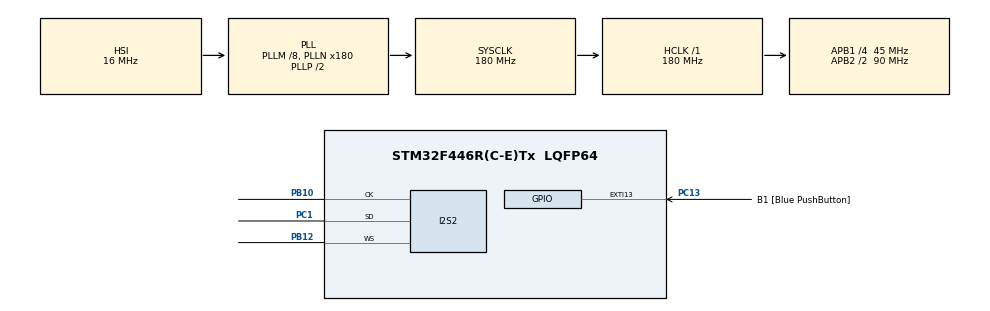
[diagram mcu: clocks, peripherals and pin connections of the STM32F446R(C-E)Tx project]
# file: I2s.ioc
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Dma.Request0=SPI2_RX
Dma.SPI2_RX.0.Direction=DMA_PERIPH_TO_MEMORY
Dma.SPI2_RX.0.FIFOMode=DMA_FIFOMODE_DISABLE
Dma.SPI2_RX.0.Instance=DMA1_Stream3
Dma.SPI2_RX.0.MemDataAlignment=DMA_MDATAALIGN_HALFWORD
Dma.SPI2_RX.0.MemInc=DMA_MINC_ENABLE
Dma.SPI2_RX.0.Mode=DMA_CIRCULAR
Dma.SPI2_RX.0.PeriphDataAlignment=DMA_PDATAALIGN_HALFWORD
Dma.SPI2_RX.0.PeriphInc=DMA_PINC_DISABLE
Dma.SPI2_RX.0.Priority=DMA_PRIORITY_LOW
FREERTOS.Tasks01=defaultTask,24,128,StartDefaultTask,Default,NULL,Dynamic,NULL,NULL
FREERTOS.configENABLE_FPU=1
I2S2.AudioFreq=I2S_AUDIOFREQ_44K
I2S2.DataFormat=I2S_DATAFORMAT_16B_EXTENDED
I2S2.ErrorAudioFreq=0.26 %
I2S2.FullDuplexMode=I2S_FULLDUPLEXMODE_DISABLE
I2S2.Instance=SPI$Index
I2S2.Mode=I2S_MODE_MASTER_RX
I2S2.RealAudioFreq=44.117 KHz
I2S2.VirtualMode=I2S_MODE_MASTER
Mcu.Family=STM32F4
Mcu.Name=STM32F446R(C-E)Tx
Mcu.Package=LQFP64
NVIC.DMA1_Stream3_IRQn=true\:5\:0\:false\:false\:true\:true\:false\:true\:true
NVIC.PriorityGroup=NVIC_PRIORITYGROUP_4
PA13.GPIO_Label=TMS
PA13.Signal=SYS_JTMS-SWDIO
PA14.GPIO_Label=TCK
PA14.Signal=SYS_JTCK-SWCLK
PA2.GPIO_Label=USART_TX
PA2.Signal=USART2_TX
PA3.GPIO_Label=USART_RX
PA3.Signal=USART2_RX
PA4.Signal=I2S1_WS
PA5.Signal=I2S1_CK
PB10.Mode=Half_Duplex_Master
PB10.Signal=I2S2_CK
PB12.Mode=Half_Duplex_Master
PB12.Signal=I2S2_WS
PB3.GPIO_Label=SWO
PB3.Signal=SYS_JTDO-SWO
PC1.Mode=Half_Duplex_Master
PC1.Signal=I2S2_SD
PC13.GPIO_Label=B1 [Blue PushButton]
PC13.GPIO_ModeDefaultEXTI=GPIO_MODE_IT_FALLING
PC13.Signal=GPXTI13
PC14-OSC32_IN.Signal=RCC_OSC32_IN
PC15-OSC32_OUT.Signal=RCC_OSC32_OUT
PH0-OSC_IN.Signal=RCC_OSC_IN
PH1-OSC_OUT.Signal=RCC_OSC_OUT
ProjectManager.HeapSize=0x200
ProjectManager.StackSize=0x400
ProjectManager.TargetToolchain=STM32CubeIDE
RCC.AHBFreq_Value=180000000
RCC.APB1CLKDivider=RCC_HCLK_DIV4
RCC.APB1Freq_Value=45000000
RCC.APB1TimFreq_Value=90000000
RCC.APB2CLKDivider=RCC_HCLK_DIV2
RCC.APB2Freq_Value=90000000
RCC.APB2TimFreq_Value=180000000
RCC.CortexFreq_Value=180000000
RCC.FLatency-AdvancedSettings=FLASH_LATENCY_5
RCC.HCLKFreq_Value=180000000
RCC.HSE_VALUE=8000000
RCC.HSI_VALUE=16000000
RCC.LSE_VALUE=32768
RCC.PLLM=8
RCC.PLLN=180
RCC.SYSCLKFreq_VALUE=180000000
RCC.SYSCLKSource=RCC_SYSCLKSOURCE_PLLCLK
RCC.USBFreq_Value=180000000
RCC.VCOOutputFreq_Value=360000000
STMicroelectronics.X-CUBE-ALGOBUILD.1.3.0.LibraryCcDSPOoLibraryJjDSPOoLibrary=true
VP_FREERTOS_VS_CMSIS_V2.Mode=CMSIS_V2
VP_MBEDTLS_VS_MBEDTLS.Mode=Enabled
VP_STMicroelectronics.X-CUBE-ALGOBUILD_VS_DSPOoLibraryJjLibrary_1.3.0_1.3.0.Mode=DSPOoLibraryJjLibrary
board=NUCLEO-F446RE

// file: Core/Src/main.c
/* USER CODE BEGIN Header */
/**
  ******************************************************************************
  * @file           : main.c
  * @brief          : Main program body
  ******************************************************************************
  * @attention
  *
  * Copyright (c) 2023 STMicroelectronics.
  * All rights reserved.
  *
  * This software is licensed under terms that can be found in the LICENSE file
  * in the root directory of this software component.
  * If no LICENSE file comes with this software, it is provided AS-IS.
  *
  ******************************************************************************
  */
/* USER CODE END Header */
#include "main.h"
#include "cmsis_os.h"
#include "mbedtls.h"
#include "arm_math.h"

I2S_HandleTypeDef hi2s2;
DMA_HandleTypeDef hdma_spi2_rx;

/* Definitions for defaultTask */
osThreadId_t defaultTaskHandle;
const osThreadAttr_t defaultTask_attributes = {
  .name = "defaultTask",
  .stack_size = 128 * 4,
  .priority = (osPriority_t) osPriorityNormal,
};
/* USER CODE BEGIN PV */
int16_t data_i2s[100];
volatile int16_t sample_i2s;
/* USER CODE END PV */

void SystemClock_Config(void);
static void MX_GPIO_Init(void);
static void MX_DMA_Init(void);
static void MX_I2S2_Init(void);
void StartDefaultTask(void *argument);

int main(void)
{

  /* MCU Configuration--------------------------------------------------------*/

  /* Reset of all peripherals, Initializes the Flash interface and the Systick. */
  HAL_Init();

  /* Configure the system clock */
  SystemClock_Config();

  /* Initialize all configured peripherals */
  MX_GPIO_Init();
  MX_DMA_Init();
  MX_I2S2_Init();
  MX_MBEDTLS_Init();
  /* Call PreOsInit function */
  MX_MBEDTLS_Init();
  /* USER CODE BEGIN 2 */
  HAL_I2S_Receive_DMA(&hi2s2, (uint8_t *)data_i2s, sizeof(data_i2s)/2);
  /* USER CODE END 2 */

  /* Init scheduler */
  osKernelInitialize();

  /* Create the thread(s) */
  /* creation of defaultTask */
  defaultTaskHandle = osThreadNew(StartDefaultTask, NULL, &defaultTask_attributes);

  /* Start scheduler */
  osKernelStart();
  /* We should never get here as control is now taken by the scheduler */
  /* Infinite loop */
  while (1)
  {

  }
}

void SystemClock_Config(void)
{
  RCC_OscInitTypeDef RCC_OscInitStruct = {0};
  RCC_ClkInitTypeDef RCC_ClkInitStruct = {0};

  /** Configure the main internal regulator output voltage
  */
  __HAL_RCC_PWR_CLK_ENABLE();
  __HAL_PWR_VOLTAGESCALING_CONFIG(PWR_REGULATOR_VOLTAGE_SCALE1);

  /** Initializes the RCC Oscillators according to the specified parameters
  * in the RCC_OscInitTypeDef structure.
  */
  RCC_OscInitStruct.OscillatorType = RCC_OSCILLATORTYPE_HSI;
  RCC_OscInitStruct.HSIState = RCC_HSI_ON;
  RCC_OscInitStruct.HSICalibrationValue = RCC_HSICALIBRATION_DEFAULT;
  RCC_OscInitStruct.PLL.PLLState = RCC_PLL_ON;
  RCC_OscInitStruct.PLL.PLLSource = RCC_PLLSOURCE_HSI;
  RCC_OscInitStruct.PLL.PLLM = 8;
  RCC_OscInitStruct.PLL.PLLN = 180;
  RCC_OscInitStruct.PLL.PLLP = RCC_PLLP_DIV2;
  RCC_OscInitStruct.PLL.PLLQ = 2;
  RCC_OscInitStruct.PLL.PLLR = 2;
  if (HAL_RCC_OscConfig(&RCC_OscInitStruct) != HAL_OK)
  {
    Error_Handler();
  }

  /** Activate the Over-Drive mode
  */
  if (HAL_PWREx_EnableOverDrive() != HAL_OK)
  {
    Error_Handler();
  }

  /** Initializes the CPU, AHB and APB buses clocks
  */
  RCC_ClkInitStruct.ClockType = RCC_CLOCKTYPE_HCLK|RCC_CLOCKTYPE_SYSCLK
                              |RCC_CLOCKTYPE_PCLK1|RCC_CLOCKTYPE_PCLK2;
  RCC_ClkInitStruct.SYSCLKSource = RCC_SYSCLKSOURCE_PLLCLK;
  RCC_ClkInitStruct.AHBCLKDivider = RCC_SYSCLK_DIV1;
  RCC_ClkInitStruct.APB1CLKDivider = RCC_HCLK_DIV4;
  RCC_ClkInitStruct.APB2CLKDivider = RCC_HCLK_DIV2;

  if (HAL_RCC_ClockConfig(&RCC_ClkInitStruct, FLASH_LATENCY_5) != HAL_OK)
  {
    Error_Handler();
  }
}

static void MX_I2S2_Init(void)
{

  hi2s2.Instance = SPI2;
  hi2s2.Init.Mode = I2S_MODE_MASTER_RX;
  hi2s2.Init.Standard = I2S_STANDARD_PHILIPS;
  hi2s2.Init.DataFormat = I2S_DATAFORMAT_16B_EXTENDED;
  hi2s2.Init.MCLKOutput = I2S_MCLKOUTPUT_DISABLE;
  hi2s2.Init.AudioFreq = I2S_AUDIOFREQ_44K;
  hi2s2.Init.CPOL = I2S_CPOL_LOW;
  hi2s2.Init.ClockSource = I2S_CLOCK_PLL;
  hi2s2.Init.FullDuplexMode = I2S_FULLDUPLEXMODE_DISABLE;
  if (HAL_I2S_Init(&hi2s2) != HAL_OK)
  {
    Error_Handler();
  }

}

static void MX_DMA_Init(void)
{

  /* DMA controller clock enable */
  __HAL_RCC_DMA1_CLK_ENABLE();

  /* DMA interrupt init */
  /* DMA1_Stream3_IRQn interrupt configuration */
  HAL_NVIC_SetPriority(DMA1_Stream3_IRQn, 5, 0);
  HAL_NVIC_EnableIRQ(DMA1_Stream3_IRQn);

}

static void MX_GPIO_Init(void)
{
  GPIO_InitTypeDef GPIO_InitStruct = {0};

  /* GPIO Ports Clock Enable */
  __HAL_RCC_GPIOC_CLK_ENABLE();
  __HAL_RCC_GPIOH_CLK_ENABLE();
  __HAL_RCC_GPIOA_CLK_ENABLE();
  __HAL_RCC_GPIOB_CLK_ENABLE();

  /*Configure GPIO pin : B1_Pin */
  GPIO_InitStruct.Pin = B1_Pin;
  GPIO_InitStruct.Mode = GPIO_MODE_IT_FALLING;
  GPIO_InitStruct.Pull = GPIO_NOPULL;
  HAL_GPIO_Init(B1_GPIO_Port, &GPIO_InitStruct);

  /*Configure GPIO pins : USART_TX_Pin USART_RX_Pin */
  GPIO_InitStruct.Pin = USART_TX_Pin|USART_RX_Pin;
  GPIO_InitStruct.Mode = GPIO_MODE_AF_PP;
  GPIO_InitStruct.Pull = GPIO_NOPULL;
  GPIO_InitStruct.Speed = GPIO_SPEED_FREQ_VERY_HIGH;
  GPIO_InitStruct.Alternate = GPIO_AF7_USART2;
  HAL_GPIO_Init(GPIOA, &GPIO_InitStruct);

  /*Configure GPIO pins : PA4 PA5 */
  GPIO_InitStruct.Pin = GPIO_PIN_4|GPIO_PIN_5;
  GPIO_InitStruct.Mode = GPIO_MODE_AF_PP;
  GPIO_InitStruct.Pull = GPIO_NOPULL;
  GPIO_InitStruct.Speed = GPIO_SPEED_FREQ_LOW;
  GPIO_InitStruct.Alternate = GPIO_AF5_SPI1;
  HAL_GPIO_Init(GPIOA, &GPIO_InitStruct);

}

/* USER CODE BEGIN 4 */
void HAL_I2S_RxCpltCallback(I2S_HandleTypeDef *hi2s)
{
	sample_i2s = data_i2s[0];
}
/* USER CODE END 4 */

void StartDefaultTask(void *argument)
{
  for(;;)
  {
    osDelay(1);
  }
}

void Error_Handler(void)
{
  __disable_irq();
  while (1)
  {
  }
}
